# SF32LB52x register map
File version: 1.0
CPU: CM33 r0p1, little endian, MPU, FPU, 3 interrupt priority bits
Registers are 32-bit, read-write, reset 0x0 unless marked. A register's access mark holds for its fields unless they carry their own. Offsets are from the block's base; [hi:lo] are bit positions; {n}, {i} and the like mark numbered series; 'fields as' and 'values as' point back to an identical list.

## TRNG — True Random Number Generator
Base 0x5000F000
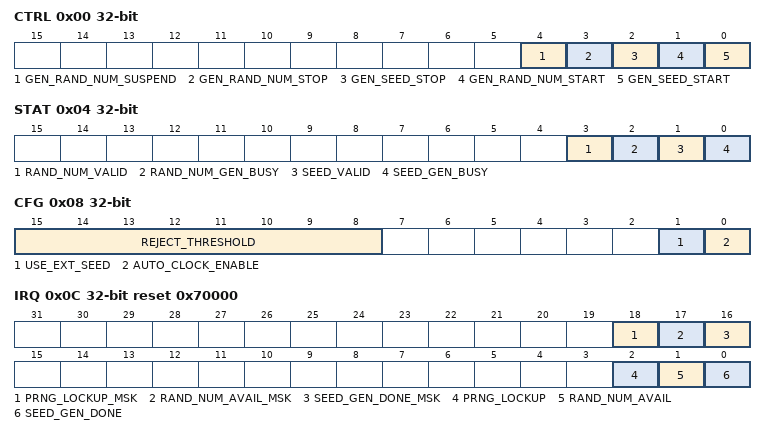
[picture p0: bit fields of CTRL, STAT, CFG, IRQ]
0x00 CTRL
  [4] GEN_RAND_NUM_SUSPEND — Set 1 to suspend random number generation and update. Set 0 to recover the process.
  [3] GEN_RAND_NUM_STOP — Set 1 to stop random number generation and update. This will reset the random number generation engine. After release the stop bit, user should write 1 to gen_rand_num_start to trigger the random number engine.
  [2] GEN_SEED_STOP — Set 1 to stop random seed generation. This will reset the random seed generation engine. After release the stop bit, user should write 1 to gen_seed_start to trigger the random seed engine.
  [1] GEN_RAND_NUM_START — write 1 to trigger the random number generation engine
  [0] GEN_SEED_START — write 1 to trigger the random seed generation engine
0x04 STAT
  [3] RAND_NUM_VALID — random number valid flag
  [2] RAND_NUM_GEN_BUSY — random number engine busy flag
  [1] SEED_VALID — random seed valid flag
  [0] SEED_GEN_BUSY — random seed engine busy flag
0x08 CFG
  [15:8] REJECT_THRESHOLD — random seed internal VN corrector check threshold
  [1] USE_EXT_SEED — set 1 to use external seed to generate random number
  [0] AUTO_CLOCK_ENABLE — auto clock gating enable
0x0C IRQ reset 0x70000
  [18] PRNG_LOCKUP_MSK — prng lockup interrupt mask
  [17] RAND_NUM_AVAIL_MSK — random number available interrupt mask
  [16] SEED_GEN_DONE_MSK — random seed generation done interrupt mask
  [2] PRNG_LOCKUP — prng lockup raw interrupt
  [1] RAND_NUM_AVAIL — random number available raw interrupt
  [0] SEED_GEN_DONE — random seed generation done raw interrupt
0x10 RAND_SEED0 — Random seed value0. If using external random seed, write value to this register will update the random seed in use.
  [31:0] VAL — Random seed value. If using external random seed, write value to this register will update the random seed in use.
{0x10+4i} RAND_SEED{i} (i=1..7) — random seed value{i}. If using external random seed, write value to this register will update the random seed in use.
  fields as RAND_SEED0
{0x30+4i} RAND_NUM{i} (i=0..7) — random number value{i}
  [31:0] VAL — random number value
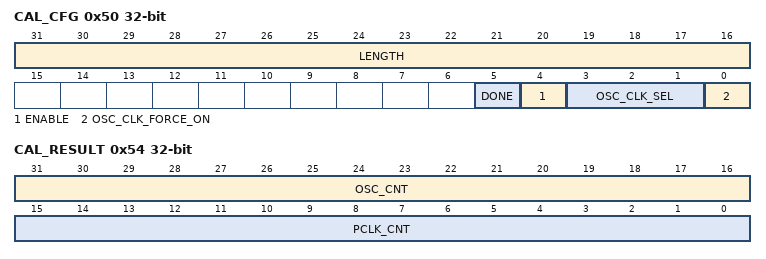
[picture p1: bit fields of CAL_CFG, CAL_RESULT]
0x50 CAL_CFG
  [31:16] LENGTH — calibration length
  [5] DONE — calibration done
  [4] ENABLE — calibration enable
  [3:1] OSC_CLK_SEL — osc clock select
  [0] OSC_CLK_FORCE_ON — osc force enable
0x54 CAL_RESULT
  [31:16] OSC_CNT — osc clock calibration counter result
  [15:0] PCLK_CNT — pclk calibration counter result

## CRC1 — Cyclic Redundancy Check
Base 0x50048000
Same registers: CRC2 0x40085000
0x00 DR — Data register
  [31:0] DR — Data register bits. This register is used to write new data to the CRC calculator. It holds the previous CRC calculation result when it is read. If the data size is less than 32 bits, the least significant bits are used to write/read the correct value.
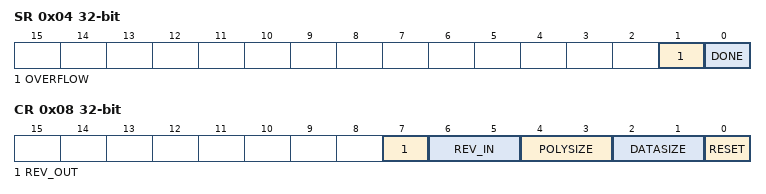
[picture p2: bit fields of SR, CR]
0x04 SR — Status register
  [1] OVERFLOW — Overflow when new data arrive while last calculation not done yet
  [0] DONE — Done flag. When DR written, done flag will be cleared automatically. The flag will assert after CRC operation of current DR finished.
0x08 CR — Control register
  [7] REV_OUT — Reverse output data This bit controls the reversal of the bit order of the output data. 0: Bit order not affected 1: Bit-reversed output format
  [6:5] REV_IN — Reverse input data These bits control the reversal of the bit order of the input data 00: Bit order not affected 01: Bit reversal done by byte 10: Bit reversal done by half-word 11: Bit reversal done by word
  [4:3] POLYSIZE — Polynomial size These bits control the size of the polynomial. 00: 32 bit polynomial 01: 16 bit polynomial 10: 8 bit polynomial 11: 7 bit polynomial
  [2:1] DATASIZE — Valid input data size These bits control the valid size of the input data. 00: lower 8-bit 01: lower 16-bit 10: lower 24-bit 11: all 32-bit
  [0] RESET — This bit is set by software to reset the CRC calculation unit and set the data register to the value stored in the CRC_INIT register. This bit can only be set, it is automatically cleared by hardware
0x10 INIT — Initial CRC value
  [31:0] INIT — Programmable initial CRC value
0x14 POL — CRC polynomial
  [31:0] POL — Programmable polynomial This register is used to write the coefficients of the polynomial to be used for CRC calculation. If the polynomial size is less than 32 bits, the least significant bits have to be used to program the correct value.
